AUTOSAR XML (schema 4-2-2)
package /STELLANTIS/EPT/ASWCs
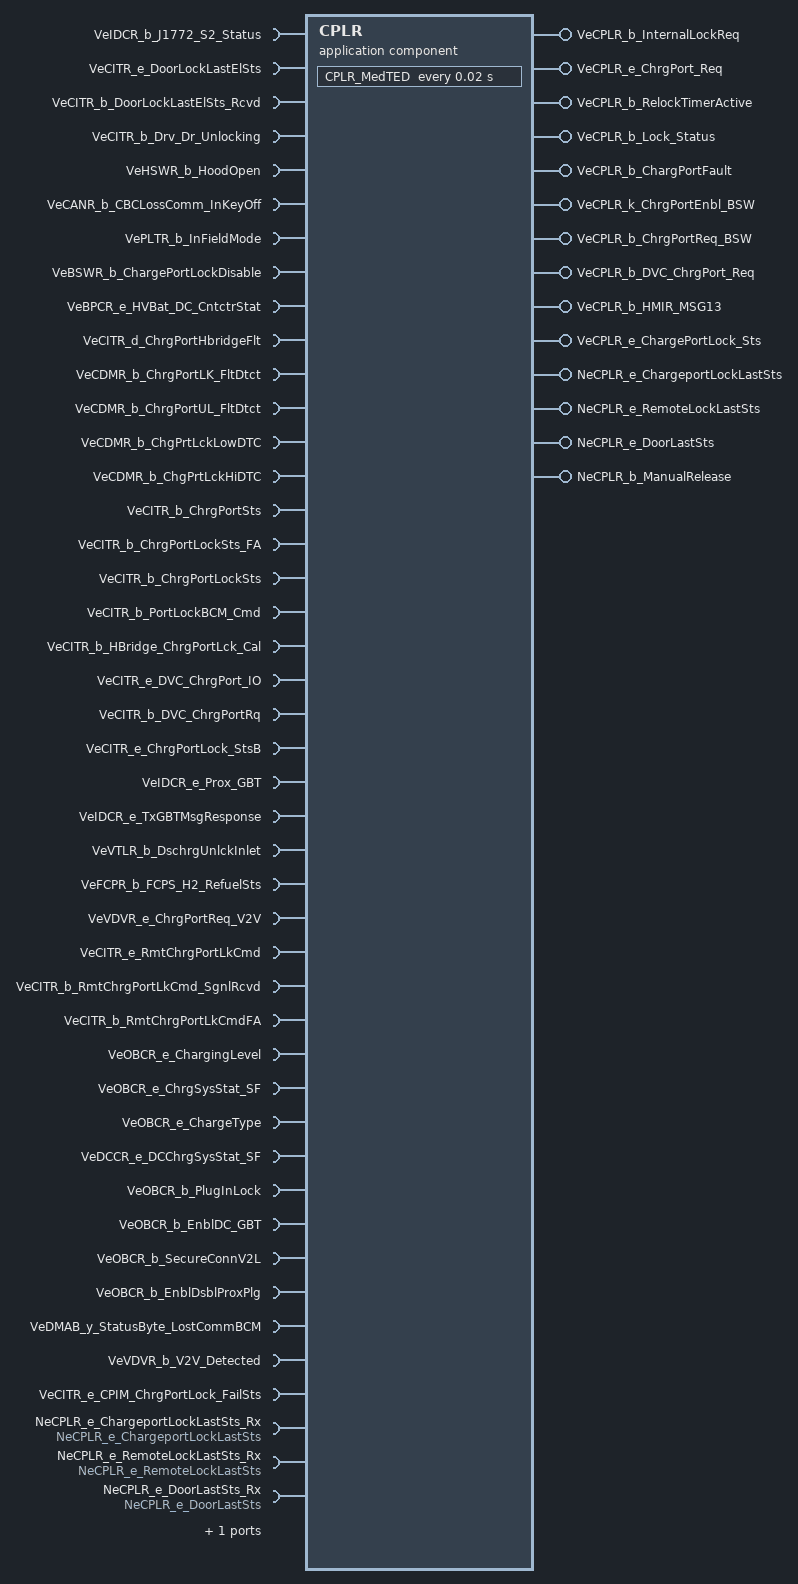
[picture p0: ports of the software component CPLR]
  application sw component type CPLR
    41 x require port:
      VeIDCR_b_J1772_S2_Status: variation-point={short-label=vpVeIDCR_b_J1772_S2_Status, sw-syscond=1}, nonqueued-receiver-com-spec{data-element=Value, init-value=0}, required-interface=VeIDCR_b_J1772_S2_Status
      VeCITR_e_DoorLockLastElSts: variation-point={short-label=vpVeCITR_e_DoorLockLastElSts, sw-syscond=1}, nonqueued-receiver-com-spec{data-element=Value, init-value=CeOBCR_e_LKD}, required-interface=VeCITR_e_DoorLockLastElSts
      VeCITR_b_DoorLockLastElSts_Rcvd: variation-point={short-label=vpVeCITR_b_DoorLockLastElSts_Rcvd, sw-syscond=1}, nonqueued-receiver-com-spec{data-element=Value, init-value=0}, required-interface=VeCITR_b_DoorLockLastElSts_Rcvd
      VeCITR_b_Drv_Dr_Unlocking: variation-point={short-label=vpVeCITR_b_Drv_Dr_Unlocking, sw-syscond=1}, nonqueued-receiver-com-spec{data-element=Value, init-value=0}, required-interface=VeCITR_b_Drv_Dr_Unlocking
      VeHSWR_b_HoodOpen: variation-point={short-label=vpVeHSWR_b_HoodOpen, sw-syscond=1}, nonqueued-receiver-com-spec{data-element=Value, init-value=0}, required-interface=VeHSWR_b_HoodOpen
      VeCANR_b_CBCLossComm_InKeyOff: variation-point={short-label=vpVeCANR_b_CBCLossComm_InKeyOff, sw-syscond=1}, nonqueued-receiver-com-spec{data-element=VeCANR_b_CBCLossComm_InKeyOff, init-value=0}, required-interface=VeCANR_b_CBCLossComm_InKeyOff
      VePLTR_b_InFieldMode: variation-point={short-label=vpVePLTR_b_InFieldMode, sw-syscond=1}, nonqueued-receiver-com-spec{data-element=Value, init-value=0}, required-interface=VePLTR_b_InFieldMode
      VeBSWR_b_ChargePortLockDisable: variation-point={short-label=vpVeBSWR_b_ChargePortLockDisable, sw-syscond=1}, nonqueued-receiver-com-spec{data-element=Value, init-value=0}, required-interface=VeBSWR_b_ChargePortLockDisable
      VeBPCR_e_HVBat_DC_CntctrStat: variation-point={short-label=vpVeBPCR_e_HVBat_DC_CntctrStat, sw-syscond=1}, nonqueued-receiver-com-spec{data-element=Value, init-value=CeBPCR_e_DCCntctrSts_Open}, required-interface=VeBPCR_e_HVBat_DC_CntctrStat
      VeCITR_d_ChrgPortHbridgeFlt: variation-point={short-label=vpVeCITR_d_ChrgPortHbridgeFlt, sw-syscond=1}, nonqueued-receiver-com-spec{data-element=Value, init-value=0}, required-interface=VeCITR_d_ChrgPortHbridgeFlt
      VeCDMR_b_ChrgPortLK_FltDtct: variation-point={short-label=vpVeCDMR_b_ChrgPortLK_FltDtct, sw-syscond=1}, nonqueued-receiver-com-spec{data-element=Value, init-value=0}, required-interface=VeCDMR_b_ChrgPortLK_FltDtct
      VeCDMR_b_ChrgPortUL_FltDtct: variation-point={short-label=vpVeCDMR_b_ChrgPortUL_FltDtct, sw-syscond=1}, nonqueued-receiver-com-spec{data-element=Value, init-value=0}, required-interface=VeCDMR_b_ChrgPortUL_FltDtct
      VeCDMR_b_ChgPrtLckLowDTC: variation-point={short-label=vpVeCDMR_b_ChgPrtLckLowDTC, sw-syscond=1}, nonqueued-receiver-com-spec{data-element=Value, init-value=0}, required-interface=VeCDMR_b_ChgPrtLckLowDTC
      VeCDMR_b_ChgPrtLckHiDTC: variation-point={short-label=vpVeCDMR_b_ChgPrtLckHiDTC, sw-syscond=1}, nonqueued-receiver-com-spec{data-element=Value, init-value=0}, required-interface=VeCDMR_b_ChgPrtLckHiDTC
      VeCITR_b_ChrgPortSts: variation-point={short-label=vpVeCITR_b_ChrgPortSts, sw-syscond=1}, nonqueued-receiver-com-spec{data-element=Value, init-value=0}, required-interface=VeCITR_b_ChrgPortSts
      VeCITR_b_ChrgPortLockSts_FA: variation-point={short-label=vpVeCITR_b_ChrgPortLockSts_FA, sw-syscond=1}, nonqueued-receiver-com-spec{data-element=Value, init-value=0}, required-interface=VeCITR_b_ChrgPortLockSts_FA
      VeCITR_b_ChrgPortLockSts: variation-point={short-label=vpVeCITR_b_ChrgPortLockSts, sw-syscond=1}, nonqueued-receiver-com-spec{data-element=Value, init-value=0}, required-interface=VeCITR_b_ChrgPortLockSts
      VeCITR_b_PortLockBCM_Cmd: variation-point={short-label=vpVeCITR_b_PortLockBCM_Cmd, sw-syscond=1}, nonqueued-receiver-com-spec{data-element=Value, init-value=0}, required-interface=VeCITR_b_PortLockBCM_Cmd
      VeCITR_b_HBridge_ChrgPortLck_Cal: variation-point={short-label=vpVeCITR_b_HBridge_ChrgPortLck_Cal, sw-syscond=1}, nonqueued-receiver-com-spec{data-element=Value, init-value=0}, required-interface=VeCITR_b_HBridge_ChrgPortLck_Cal
      VeCITR_e_DVC_ChrgPort_IO: variation-point={short-label=vpVeCITR_e_DVC_ChrgPort_IO, sw-syscond=1}, nonqueued-receiver-com-spec{data-element=Value, init-value=CeODCR_e_Return_ECU_Cntrl}, required-interface=VeCITR_e_DVC_ChrgPort_IO
      VeCITR_b_DVC_ChrgPortRq: variation-point={short-label=vpVeCITR_b_DVC_ChrgPortRq, sw-syscond=1}, nonqueued-receiver-com-spec{data-element=Value, init-value=0}, required-interface=VeCITR_b_DVC_ChrgPortRq
      VeCITR_e_ChrgPortLock_StsB: variation-point={short-label=vpVeCITR_e_ChrgPortLock_StsB, sw-syscond=1}, nonqueued-receiver-com-spec{data-element=Value, init-value=CeOBCR_e_DefaultLock_Sts}, required-interface=VeCITR_e_ChrgPortLock_StsB
      VeIDCR_e_Prox_GBT: variation-point={short-label=vpVeIDCR_e_Prox_GBT, sw-syscond=1}, nonqueued-receiver-com-spec{data-element=Value, init-value=CeIDCR_e_CC_LO}, required-interface=VeIDCR_e_Prox_GBT
      VeIDCR_e_TxGBTMsgResponse: variation-point={short-label=vpVeIDCR_e_TxGBTMsgResponse, sw-syscond=1}, nonqueued-receiver-com-spec{data-element=Value, init-value=CeIDCR_e_GBTRes_EVSE_Not_Connected}, required-interface=VeIDCR_e_TxGBTMsgResponse
      VeVTLR_b_DschrgUnlckInlet: variation-point={short-label=vpVeVTLR_b_DschrgUnlckInlet, sw-syscond=1}, nonqueued-receiver-com-spec{data-element=Value, init-value=0}, required-interface=VeVTLR_b_DschrgUnlckInlet
      VeFCPR_b_FCPS_H2_RefuelSts: variation-point={short-label=vpVeFCPR_b_FCPS_H2_RefuelSts, sw-syscond=1}, nonqueued-receiver-com-spec{data-element=Value, init-value=0}, required-interface=VeFCPR_b_FCPS_H2_RefuelSts
      VeVDVR_e_ChrgPortReq_V2V: variation-point={short-label=vpVeVDVR_e_ChrgPortReq_V2V, sw-syscond=1}, nonqueued-receiver-com-spec{data-element=Value, init-value=CeOBCR_e_PortNoRequest}, required-interface=VeVDVR_e_ChrgPortReq_V2V
      VeCITR_e_RmtChrgPortLkCmd: variation-point={short-label=vpVeCITR_e_RmtChrgPortLkCmd, sw-syscond=1}, nonqueued-receiver-com-spec{data-element=Value, init-value=CeCITR_e_Default}, required-interface=VeCITR_e_RmtChrgPortLkCmd
      VeCITR_b_RmtChrgPortLkCmd_SgnlRcvd: variation-point={short-label=vpVeCITR_b_RmtChrgPortLkCmd_SgnlRcvd, sw-syscond=1}, nonqueued-receiver-com-spec{data-element=Value, init-value=0}, required-interface=VeCITR_b_RmtChrgPortLkCmd_SgnlRcvd
      VeCITR_b_RmtChrgPortLkCmdFA: variation-point={short-label=vpVeCITR_b_RmtChrgPortLkCmdFA, sw-syscond=1}, nonqueued-receiver-com-spec{data-element=Value, init-value=0}, required-interface=VeCITR_b_RmtChrgPortLkCmdFA
      VeOBCR_e_ChargingLevel: variation-point={short-label=vpVeOBCR_e_ChargingLevel, sw-syscond=1}, nonqueued-receiver-com-spec{data-element=Value, init-value=CeOBCR_e_ChargingLvlDefault}, required-interface=VeOBCR_e_ChargingLevel
      VeOBCR_e_ChrgSysStat_SF: variation-point={short-label=vpVeOBCR_e_ChrgSysStat_SF, sw-syscond=1}, nonqueued-receiver-com-spec{data-element=Value, init-value=CeOBCR_e_PowerUp}, required-interface=VeOBCR_e_ChrgSysStat_SF
      VeOBCR_e_ChargeType: variation-point={short-label=vpVeOBCR_e_ChargeType, sw-syscond=1}, nonqueued-receiver-com-spec{data-element=Value, init-value=CeOBCR_e_AC}, required-interface=VeOBCR_e_ChargeType
      VeDCCR_e_DCChrgSysStat_SF: variation-point={short-label=vpVeDCCR_e_DCChrgSysStat_SF, sw-syscond=1}, nonqueued-receiver-com-spec{data-element=Value, init-value=CeOBCR_e_DCinit}, required-interface=VeDCCR_e_DCChrgSysStat_SF
      VeOBCR_b_PlugInLock: variation-point={short-label=vpVeOBCR_b_PlugInLock, sw-syscond=1}, nonqueued-receiver-com-spec{data-element=Value, init-value=0}, required-interface=VeOBCR_b_PlugInLock
      VeOBCR_b_EnblDC_GBT: variation-point={short-label=vpVeOBCR_b_EnblDC_GBT, sw-syscond=1}, nonqueued-receiver-com-spec{data-element=Value, init-value=0}, required-interface=VeOBCR_b_EnblDC_GBT
      VeOBCR_b_SecureConnV2L: variation-point={short-label=vpVeOBCR_b_SecureConnV2L, sw-syscond=1}, nonqueued-receiver-com-spec{data-element=Value, init-value=0}, required-interface=VeOBCR_b_SecureConnV2L
      VeOBCR_b_EnblDsblProxPlg: variation-point={short-label=vpVeOBCR_b_EnblDsblProxPlg, sw-syscond=1}, nonqueued-receiver-com-spec{data-element=Value, init-value=0}, required-interface=VeOBCR_b_EnblDsblProxPlg
      VeDMAB_y_StatusByte_LostCommBCM: variation-point={short-label=vpVeDMAB_y_StatusByte_LostCommBCM, sw-syscond=1}, nonqueued-receiver-com-spec{data-element=Value, init-value=0}, required-interface=VeDMAB_y_StatusByte_LostCommBCM
      VeVDVR_b_V2V_Detected: variation-point={short-label=vpVeVDVR_b_V2V_Detected, sw-syscond=1}, nonqueued-receiver-com-spec{data-element=Value, init-value=0}, required-interface=VeVDVR_b_V2V_Detected
      VeCITR_e_CPIM_ChrgPortLock_FailSts: variation-point={short-label=vpVeCITR_e_CPIM_ChrgPortLock_FailSts, sw-syscond=1}, nonqueued-receiver-com-spec{data-element=Value, init-value=CeCITR_e_CPIMLock_Nofailure}, required-interface=VeCITR_e_CPIM_ChrgPortLock_FailSts
    10 x provide port:
      VeCPLR_b_InternalLockReq: nonqueued-sender-com-spec{data-element=Value, init-value=0}, provided-interface=VeCPLR_b_InternalLockReq
      VeCPLR_e_ChrgPort_Req: nonqueued-sender-com-spec{data-element=Value, init-value=CeOBCR_e_PortNoRequest}, provided-interface=VeCPLR_e_ChrgPort_Req
      VeCPLR_b_RelockTimerActive: nonqueued-sender-com-spec{data-element=Value, init-value=0}, provided-interface=VeCPLR_b_RelockTimerActive
      VeCPLR_b_Lock_Status: nonqueued-sender-com-spec{data-element=Value, init-value=0}, provided-interface=VeCPLR_b_Lock_Status
      VeCPLR_b_ChargPortFault: nonqueued-sender-com-spec{data-element=Value, init-value=0}, provided-interface=VeCPLR_b_ChargPortFault
      VeCPLR_k_ChrgPortEnbl_BSW: nonqueued-sender-com-spec{data-element=Value, init-value=0}, provided-interface=VeCPLR_k_ChrgPortEnbl_BSW
      VeCPLR_b_ChrgPortReq_BSW: nonqueued-sender-com-spec{data-element=Value, init-value=0}, provided-interface=VeCPLR_b_ChrgPortReq_BSW
      VeCPLR_b_DVC_ChrgPort_Req: nonqueued-sender-com-spec{data-element=Value, init-value=0}, provided-interface=VeCPLR_b_DVC_ChrgPort_Req
      VeCPLR_b_HMIR_MSG13: nonqueued-sender-com-spec{data-element=Value, init-value=0}, provided-interface=VeCPLR_b_HMIR_MSG13
      VeCPLR_e_ChargePortLock_Sts: nonqueued-sender-com-spec{data-element=Value, init-value=CeOBCR_e_PortLockSts_Default}, provided-interface=VeCPLR_e_ChargePortLock_Sts
    4 x require port:
      NeCPLR_e_ChargeportLockLastSts_Rx: variation-point={short-label=vpNeCPLR_e_ChargeportLockLastSts_Rx, sw-syscond=1}, nv-require-com-spec{init-value=CeOBCR_e_PortLockSts_Default, variable=NeCPLR_e_ChargeportLockLastSts}, required-interface=NeCPLR_e_ChargeportLockLastSts
      NeCPLR_e_RemoteLockLastSts_Rx: variation-point={short-label=vpNeCPLR_e_RemoteLockLastSts_Rx, sw-syscond=1}, nv-require-com-spec{init-value=CeCITR_e_Default, variable=NeCPLR_e_RemoteLockLastSts}, required-interface=NeCPLR_e_RemoteLockLastSts
      NeCPLR_e_DoorLastSts_Rx: variation-point={short-label=vpNeCPLR_e_DoorLastSts_Rx, sw-syscond=1}, nv-require-com-spec{init-value=CeOBCR_e_LKD, variable=NeCPLR_e_DoorLastSts}, required-interface=NeCPLR_e_DoorLastSts
      NeCPLR_b_ManualRelease_Rx: variation-point={short-label=vpNeCPLR_b_ManualRelease_Rx, sw-syscond=1}, nv-require-com-spec{init-value=0, variable=NeCPLR_b_ManualRelease}, required-interface=NeCPLR_b_ManualRelease
    4 x provide port:
      NeCPLR_e_ChargeportLockLastSts: variation-point={short-label=vpNeCPLR_e_ChargeportLockLastSts, sw-syscond=1}, nv-provide-com-spec{ram-block-init-value=CeOBCR_e_PortLockSts_Default, variable=NeCPLR_e_ChargeportLockLastSts}, provided-interface=NeCPLR_e_ChargeportLockLastSts
      NeCPLR_e_RemoteLockLastSts: variation-point={short-label=vpNeCPLR_e_RemoteLockLastSts, sw-syscond=1}, nv-provide-com-spec{ram-block-init-value=CeCITR_e_Default, variable=NeCPLR_e_RemoteLockLastSts}, provided-interface=NeCPLR_e_RemoteLockLastSts
      NeCPLR_e_DoorLastSts: variation-point={short-label=vpNeCPLR_e_DoorLastSts, sw-syscond=1}, nv-provide-com-spec{ram-block-init-value=CeOBCR_e_LKD, variable=NeCPLR_e_DoorLastSts}, provided-interface=NeCPLR_e_DoorLastSts
      NeCPLR_b_ManualRelease: variation-point={short-label=vpNeCPLR_b_ManualRelease, sw-syscond=1}, nv-provide-com-spec{ram-block-init-value=0, variable=NeCPLR_b_ManualRelease}, provided-interface=NeCPLR_b_ManualRelease
    behavior IB_CPLR: data-type-mapping=msADTtoIDTMapping, handle-termination-and-restart=NO-SUPPORT
      timing event Event_MedTED: start-on-event=CPLR_MedTED, period=0.02
      init event Event_CPLR_ac_Init: start-on-event=CPLR_ac_Init
      init event Event_PwrOn: start-on-event=CPLR_PwrOn
      init event Event_PwrOff: start-on-event=CPLR_PwrOff
      4 x runnable:
        CPLR_ac_Init
          data-send-points:
            access OUT_VeCPLR_e_ChrgPort_Req_Value: accessed-variable=VeCPLR_e_ChrgPort_Req.Value
            access OUT_VeCPLR_e_ChargePortLock_Sts_Value: accessed-variable=VeCPLR_e_ChargePortLock_Sts.Value
        CPLR_PwrOn
          data-receive-point-by-arguments:
            4 x access:
              IN_NeCPLR_b_ManualRelease_Rx_NeCPLR_b_ManualRelease: accessed-variable=NeCPLR_b_ManualRelease_Rx.NeCPLR_b_ManualRelease, variation-point={short-label=vpIN_NeCPLR_b_ManualRelease_Rx_NeCPLR_b_ManualRelease, sw-syscond=1}
              IN_NeCPLR_e_ChargeportLockLastSts_Rx_NeCPLR_e_ChargeportLockLastSts: accessed-variable=NeCPLR_e_ChargeportLockLastSts_Rx.NeCPLR_e_ChargeportLockLastSts, variation-point={short-label=vpIN_NeCPLR_e_ChargeportLockLastSts_Rx_NeCPLR_e_ChargeportLockLastSts, sw-syscond=1}
              IN_NeCPLR_e_DoorLastSts_Rx_NeCPLR_e_DoorLastSts: accessed-variable=NeCPLR_e_DoorLastSts_Rx.NeCPLR_e_DoorLastSts, variation-point={short-label=vpIN_NeCPLR_e_DoorLastSts_Rx_NeCPLR_e_DoorLastSts, sw-syscond=1}
              IN_NeCPLR_e_RemoteLockLastSts_Rx_NeCPLR_e_RemoteLockLastSts: accessed-variable=NeCPLR_e_RemoteLockLastSts_Rx.NeCPLR_e_RemoteLockLastSts, variation-point={short-label=vpIN_NeCPLR_e_RemoteLockLastSts_Rx_NeCPLR_e_RemoteLockLastSts, sw-syscond=1}
          data-send-points:
            10 x access:
              OUT_VeCPLR_e_ChrgPort_Req_Value: accessed-variable=VeCPLR_e_ChrgPort_Req.Value
              OUT_VeCPLR_b_DVC_ChrgPort_Req_Value: accessed-variable=VeCPLR_b_DVC_ChrgPort_Req.Value
              OUT_VeCPLR_b_Lock_Status_Value: accessed-variable=VeCPLR_b_Lock_Status.Value
              OUT_VeCPLR_b_RelockTimerActive_Value: accessed-variable=VeCPLR_b_RelockTimerActive.Value
              OUT_VeCPLR_b_HMIR_MSG13_Value: accessed-variable=VeCPLR_b_HMIR_MSG13.Value
              OUT_VeCPLR_b_ChrgPortReq_BSW_Value: accessed-variable=VeCPLR_b_ChrgPortReq_BSW.Value
              OUT_VeCPLR_k_ChrgPortEnbl_BSW_Value: accessed-variable=VeCPLR_k_ChrgPortEnbl_BSW.Value
              OUT_VeCPLR_b_InternalLockReq_Value: accessed-variable=VeCPLR_b_InternalLockReq.Value
              OUT_VeCPLR_b_ChargPortFault_Value: accessed-variable=VeCPLR_b_ChargPortFault.Value
              OUT_VeCPLR_e_ChargePortLock_Sts_Value: accessed-variable=VeCPLR_e_ChargePortLock_Sts.Value
        CPLR_MedTED: variation-point={short-label=vpCPLR_MedTED, sw-syscond=1}
          data-receive-point-by-arguments:
            41 x access:
              IN_VeBPCR_e_HVBat_DC_CntctrStat_Value: accessed-variable=VeBPCR_e_HVBat_DC_CntctrStat.Value, variation-point={short-label=vpIN_VeBPCR_e_HVBat_DC_CntctrStat_Value, sw-syscond=1}
              IN_VeBSWR_b_ChargePortLockDisable_Value: accessed-variable=VeBSWR_b_ChargePortLockDisable.Value, variation-point={short-label=vpIN_VeBSWR_b_ChargePortLockDisable_Value, sw-syscond=1}
              IN_VeCANR_b_CBCLossComm_InKeyOff_VeCANR_b_CBCLossComm_InKeyOff: accessed-variable=VeCANR_b_CBCLossComm_InKeyOff.VeCANR_b_CBCLossComm_InKeyOff, variation-point={short-label=vpIN_VeCANR_b_CBCLossComm_InKeyOff_VeCANR_b_CBCLossComm_InKeyOff, sw-syscond=1}
              IN_VeCDMR_b_ChgPrtLckHiDTC_Value: accessed-variable=VeCDMR_b_ChgPrtLckHiDTC.Value, variation-point={short-label=vpIN_VeCDMR_b_ChgPrtLckHiDTC_Value, sw-syscond=1}
              IN_VeCDMR_b_ChgPrtLckLowDTC_Value: accessed-variable=VeCDMR_b_ChgPrtLckLowDTC.Value, variation-point={short-label=vpIN_VeCDMR_b_ChgPrtLckLowDTC_Value, sw-syscond=1}
              IN_VeCDMR_b_ChrgPortLK_FltDtct_Value: accessed-variable=VeCDMR_b_ChrgPortLK_FltDtct.Value, variation-point={short-label=vpIN_VeCDMR_b_ChrgPortLK_FltDtct_Value, sw-syscond=1}
              IN_VeCDMR_b_ChrgPortUL_FltDtct_Value: accessed-variable=VeCDMR_b_ChrgPortUL_FltDtct.Value, variation-point={short-label=vpIN_VeCDMR_b_ChrgPortUL_FltDtct_Value, sw-syscond=1}
              IN_VeCITR_b_ChrgPortLockSts_Value: accessed-variable=VeCITR_b_ChrgPortLockSts.Value, variation-point={short-label=vpIN_VeCITR_b_ChrgPortLockSts_Value, sw-syscond=1}
              IN_VeCITR_b_ChrgPortLockSts_FA_Value: accessed-variable=VeCITR_b_ChrgPortLockSts_FA.Value, variation-point={short-label=vpIN_VeCITR_b_ChrgPortLockSts_FA_Value, sw-syscond=1}
              IN_VeCITR_b_ChrgPortSts_Value: accessed-variable=VeCITR_b_ChrgPortSts.Value, variation-point={short-label=vpIN_VeCITR_b_ChrgPortSts_Value, sw-syscond=1}
              IN_VeCITR_b_DVC_ChrgPortRq_Value: accessed-variable=VeCITR_b_DVC_ChrgPortRq.Value, variation-point={short-label=vpIN_VeCITR_b_DVC_ChrgPortRq_Value, sw-syscond=1}
              IN_VeCITR_b_DoorLockLastElSts_Rcvd_Value: accessed-variable=VeCITR_b_DoorLockLastElSts_Rcvd.Value, variation-point={short-label=vpIN_VeCITR_b_DoorLockLastElSts_Rcvd_Value, sw-syscond=1}
              IN_VeCITR_b_Drv_Dr_Unlocking_Value: accessed-variable=VeCITR_b_Drv_Dr_Unlocking.Value, variation-point={short-label=vpIN_VeCITR_b_Drv_Dr_Unlocking_Value, sw-syscond=1}
              IN_VeCITR_b_HBridge_ChrgPortLck_Cal_Value: accessed-variable=VeCITR_b_HBridge_ChrgPortLck_Cal.Value, variation-point={short-label=vpIN_VeCITR_b_HBridge_ChrgPortLck_Cal_Value, sw-syscond=1}
              IN_VeCITR_b_PortLockBCM_Cmd_Value: accessed-variable=VeCITR_b_PortLockBCM_Cmd.Value, variation-point={short-label=vpIN_VeCITR_b_PortLockBCM_Cmd_Value, sw-syscond=1}
              IN_VeCITR_b_RmtChrgPortLkCmdFA_Value: accessed-variable=VeCITR_b_RmtChrgPortLkCmdFA.Value, variation-point={short-label=vpIN_VeCITR_b_RmtChrgPortLkCmdFA_Value, sw-syscond=1}
              IN_VeCITR_b_RmtChrgPortLkCmd_SgnlRcvd_Value: accessed-variable=VeCITR_b_RmtChrgPortLkCmd_SgnlRcvd.Value, variation-point={short-label=vpIN_VeCITR_b_RmtChrgPortLkCmd_SgnlRcvd_Value, sw-syscond=1}
              IN_VeCITR_d_ChrgPortHbridgeFlt_Value: accessed-variable=VeCITR_d_ChrgPortHbridgeFlt.Value, variation-point={short-label=vpIN_VeCITR_d_ChrgPortHbridgeFlt_Value, sw-syscond=1}
              IN_VeCITR_e_CPIM_ChrgPortLock_FailSts_Value: accessed-variable=VeCITR_e_CPIM_ChrgPortLock_FailSts.Value, variation-point={short-label=vpIN_VeCITR_e_CPIM_ChrgPortLock_FailSts_Value, sw-syscond=1}
              IN_VeCITR_e_ChrgPortLock_StsB_Value: accessed-variable=VeCITR_e_ChrgPortLock_StsB.Value, variation-point={short-label=vpIN_VeCITR_e_ChrgPortLock_StsB_Value, sw-syscond=1}
              IN_VeCITR_e_DVC_ChrgPort_IO_Value: accessed-variable=VeCITR_e_DVC_ChrgPort_IO.Value, variation-point={short-label=vpIN_VeCITR_e_DVC_ChrgPort_IO_Value, sw-syscond=1}
              IN_VeCITR_e_DoorLockLastElSts_Value: accessed-variable=VeCITR_e_DoorLockLastElSts.Value, variation-point={short-label=vpIN_VeCITR_e_DoorLockLastElSts_Value, sw-syscond=1}
              IN_VeCITR_e_RmtChrgPortLkCmd_Value: accessed-variable=VeCITR_e_RmtChrgPortLkCmd.Value, variation-point={short-label=vpIN_VeCITR_e_RmtChrgPortLkCmd_Value, sw-syscond=1}
              IN_VeDCCR_e_DCChrgSysStat_SF_Value: accessed-variable=VeDCCR_e_DCChrgSysStat_SF.Value, variation-point={short-label=vpIN_VeDCCR_e_DCChrgSysStat_SF_Value, sw-syscond=1}
              IN_VeDMAB_y_StatusByte_LostCommBCM_Value: accessed-variable=VeDMAB_y_StatusByte_LostCommBCM.Value, variation-point={short-label=vpIN_VeDMAB_y_StatusByte_LostCommBCM_Value, sw-syscond=1}
              IN_VeFCPR_b_FCPS_H2_RefuelSts_Value: accessed-variable=VeFCPR_b_FCPS_H2_RefuelSts.Value, variation-point={short-label=vpIN_VeFCPR_b_FCPS_H2_RefuelSts_Value, sw-syscond=1}
              IN_VeHSWR_b_HoodOpen_Value: accessed-variable=VeHSWR_b_HoodOpen.Value, variation-point={short-label=vpIN_VeHSWR_b_HoodOpen_Value, sw-syscond=1}
              IN_VeIDCR_b_J1772_S2_Status_Value: accessed-variable=VeIDCR_b_J1772_S2_Status.Value, variation-point={short-label=vpIN_VeIDCR_b_J1772_S2_Status_Value, sw-syscond=1}
              IN_VeIDCR_e_Prox_GBT_Value: accessed-variable=VeIDCR_e_Prox_GBT.Value, variation-point={short-label=vpIN_VeIDCR_e_Prox_GBT_Value, sw-syscond=1}
              IN_VeIDCR_e_TxGBTMsgResponse_Value: accessed-variable=VeIDCR_e_TxGBTMsgResponse.Value, variation-point={short-label=vpIN_VeIDCR_e_TxGBTMsgResponse_Value, sw-syscond=1}
              IN_VeOBCR_b_EnblDC_GBT_Value: accessed-variable=VeOBCR_b_EnblDC_GBT.Value, variation-point={short-label=vpIN_VeOBCR_b_EnblDC_GBT_Value, sw-syscond=1}
              IN_VeOBCR_b_EnblDsblProxPlg_Value: accessed-variable=VeOBCR_b_EnblDsblProxPlg.Value, variation-point={short-label=vpIN_VeOBCR_b_EnblDsblProxPlg_Value, sw-syscond=1}
              IN_VeOBCR_b_PlugInLock_Value: accessed-variable=VeOBCR_b_PlugInLock.Value, variation-point={short-label=vpIN_VeOBCR_b_PlugInLock_Value, sw-syscond=1}
              IN_VeOBCR_b_SecureConnV2L_Value: accessed-variable=VeOBCR_b_SecureConnV2L.Value, variation-point={short-label=vpIN_VeOBCR_b_SecureConnV2L_Value, sw-syscond=1}
              IN_VeOBCR_e_ChargeType_Value: accessed-variable=VeOBCR_e_ChargeType.Value, variation-point={short-label=vpIN_VeOBCR_e_ChargeType_Value, sw-syscond=1}
              IN_VeOBCR_e_ChargingLevel_Value: accessed-variable=VeOBCR_e_ChargingLevel.Value, variation-point={short-label=vpIN_VeOBCR_e_ChargingLevel_Value, sw-syscond=1}
              IN_VeOBCR_e_ChrgSysStat_SF_Value: accessed-variable=VeOBCR_e_ChrgSysStat_SF.Value, variation-point={short-label=vpIN_VeOBCR_e_ChrgSysStat_SF_Value, sw-syscond=1}
              IN_VePLTR_b_InFieldMode_Value: accessed-variable=VePLTR_b_InFieldMode.Value, variation-point={short-label=vpIN_VePLTR_b_InFieldMode_Value, sw-syscond=1}
              IN_VeVDVR_b_V2V_Detected_Value: accessed-variable=VeVDVR_b_V2V_Detected.Value, variation-point={short-label=vpIN_VeVDVR_b_V2V_Detected_Value, sw-syscond=1}
              IN_VeVDVR_e_ChrgPortReq_V2V_Value: accessed-variable=VeVDVR_e_ChrgPortReq_V2V.Value, variation-point={short-label=vpIN_VeVDVR_e_ChrgPortReq_V2V_Value, sw-syscond=1}
              IN_VeVTLR_b_DschrgUnlckInlet_Value: accessed-variable=VeVTLR_b_DschrgUnlckInlet.Value, variation-point={short-label=vpIN_VeVTLR_b_DschrgUnlckInlet_Value, sw-syscond=1}
          data-send-points:
            10 x access:
              OUT_VeCPLR_b_RelockTimerActive_Value: accessed-variable=VeCPLR_b_RelockTimerActive.Value
              OUT_VeCPLR_e_ChrgPort_Req_Value: accessed-variable=VeCPLR_e_ChrgPort_Req.Value
              OUT_VeCPLR_b_Lock_Status_Value: accessed-variable=VeCPLR_b_Lock_Status.Value
              OUT_VeCPLR_b_ChrgPortReq_BSW_Value: accessed-variable=VeCPLR_b_ChrgPortReq_BSW.Value
              OUT_VeCPLR_k_ChrgPortEnbl_BSW_Value: accessed-variable=VeCPLR_k_ChrgPortEnbl_BSW.Value
              OUT_VeCPLR_e_ChargePortLock_Sts_Value: accessed-variable=VeCPLR_e_ChargePortLock_Sts.Value
              OUT_VeCPLR_b_InternalLockReq_Value: accessed-variable=VeCPLR_b_InternalLockReq.Value
              OUT_VeCPLR_b_ChargPortFault_Value: accessed-variable=VeCPLR_b_ChargPortFault.Value
              OUT_VeCPLR_b_HMIR_MSG13_Value: accessed-variable=VeCPLR_b_HMIR_MSG13.Value
              OUT_VeCPLR_b_DVC_ChrgPort_Req_Value: accessed-variable=VeCPLR_b_DVC_ChrgPort_Req.Value
        CPLR_PwrOff: variation-point={short-label=vpCPLR_PwrOff, sw-syscond=1}
          data-send-points:
            4 x access:
              OUT_NeCPLR_e_ChargeportLockLastSts_NeCPLR_e_ChargeportLockLastSts: accessed-variable=NeCPLR_e_ChargeportLockLastSts.NeCPLR_e_ChargeportLockLastSts, variation-point={short-label=vpOUT_NeCPLR_e_ChargeportLockLastSts_NeCPLR_e_ChargeportLockLastSts, sw-syscond=1}
              OUT_NeCPLR_e_RemoteLockLastSts_NeCPLR_e_RemoteLockLastSts: accessed-variable=NeCPLR_e_RemoteLockLastSts.NeCPLR_e_RemoteLockLastSts, variation-point={short-label=vpOUT_NeCPLR_e_RemoteLockLastSts_NeCPLR_e_RemoteLockLastSts, sw-syscond=1}
              OUT_NeCPLR_e_DoorLastSts_NeCPLR_e_DoorLastSts: accessed-variable=NeCPLR_e_DoorLastSts.NeCPLR_e_DoorLastSts, variation-point={short-label=vpOUT_NeCPLR_e_DoorLastSts_NeCPLR_e_DoorLastSts, sw-syscond=1}
              OUT_NeCPLR_b_ManualRelease_NeCPLR_b_ManualRelease: accessed-variable=NeCPLR_b_ManualRelease.NeCPLR_b_ManualRelease, variation-point={short-label=vpOUT_NeCPLR_b_ManualRelease_NeCPLR_b_ManualRelease, sw-syscond=1}
      variation point proxy Variant_CPLR_1: category=CONDITION, condition-access=1
